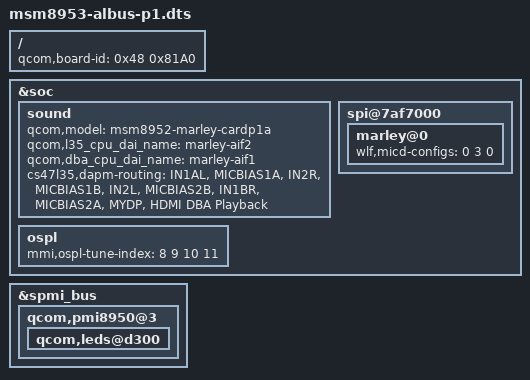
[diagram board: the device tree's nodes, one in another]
/* Copyright (c) 2016, Motorola Mobility Inc. All rights reserved.
 *
 * This program is free software; you can redistribute it and/or modify
 * it under the terms of the GNU General Public License version 2 and
 * only version 2 as published by the Free Software Foundation.
 *
 * This program is distributed in the hope that it will be useful,
 * but WITHOUT ANY WARRANTY; without even the implied warranty of
 * MERCHANTABILITY or FITNESS FOR A PARTICULAR PURPOSE.  See the
 * GNU General Public License for more details.
 */

/dts-v1/;


#include "msm8953-albus.dtsi"


/ {
	qcom,board-id = <0x48 0x81A0>;
};

&soc {
	sound {
		qcom,model = "msm8952-marley-cardp1a";
		qcom,l35_cpu_dai_name = "marley-aif2";
		qcom,dba_cpu_dai_name = "marley-aif1";
		cs47l35,dapm-routing =
			"IN1AL", "MICBIAS1A",
			"IN2R", "MICBIAS1B",
			"IN2L", "MICBIAS2B",
			"IN1BR", "MICBIAS2A",
			"MYDP", "HDMI DBA Playback";
	};

	ospl {
		mmi,ospl-tune-index = <8 9 10 11>;
	};

	spi@7af7000 {
		marley@0 {
			wlf,micd-configs = <0 3 0>;
		};
	};
};

&spmi_bus {
	qcom,pmi8950@3 {
		qcom,leds@d300 {
			/delete-property/ qcom,self-check-enabled;
		};
	};
};
